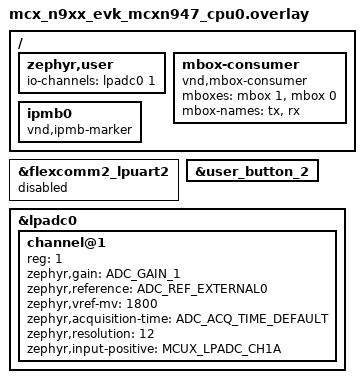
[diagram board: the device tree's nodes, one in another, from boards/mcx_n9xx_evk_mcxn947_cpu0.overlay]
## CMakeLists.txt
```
# SPDX-License-Identifier: Apache-2.0
#
# Full board port: builds real common/ subsystems (hal_wdt, hal_i2c,
# lib/timer, lib/libutil, sensor framework, FRU/eeprom, IPMI/IPMB)
# ported to mainline Zephyr's API surface, in place of the bring-up
# branch's from-scratch stand-ins. See README.md for exactly what was
# ported, what's stubbed, and why.

cmake_minimum_required(VERSION 3.20.0)

# DMTF libspdm (SPDM attestation responder, see src/plat_spdm.c) is
# pulled in as an extra Zephyr module so its zephyr_library() registers
# before find_package(Zephyr) finalises ZEPHYR_LIBS. Must precede it.
list(APPEND ZEPHYR_EXTRA_MODULES ${CMAKE_CURRENT_SOURCE_DIR}/libspdm)

find_package(Zephyr REQUIRED HINTS $ENV{ZEPHYR_BASE})
project(mcx-n9xx-evk)

set(common_path ${CMAKE_CURRENT_SOURCE_DIR}/../../common)

target_sources(app PRIVATE
  src/main.c
  src/plat_gpio.c
  src/plat_hwinfo.c
  src/plat_mbox.c
  src/plat_shell.c
  src/plat_storage.c
  src/plat_sensor_table.c
  src/plat_sdr_table.c
  src/plat_fru.c
  src/plat_ipmb.c
  src/plat_mctp.c
  src/plat_pldm_monitor.c
  src/plat_spdm.c
  src/plat_spdm_platform.c
  src/plat_stubs.c
  ${common_path}/lib/timer.c
  ${common_path}/lib/libutil.c
  ${common_path}/lib/util_pmbus.c
  ${common_path}/hal/hal_wdt.c
  ${common_path}/hal/hal_i2c.c
  ${common_path}/service/sensor/sensor.c
  ${common_path}/service/sensor/sdr.c
  ${common_path}/service/mctp/mctp.c
  ${common_path}/service/mctp/mctp_ctrl.c
  ${common_path}/service/mctp/mctp_smbus.c
  ${common_path}/service/pldm/pldm.c
  ${common_path}/service/pldm/pldm_base.c
  ${common_path}/service/pldm/pldm_oem.c
  ${common_path}/service/pldm/pldm_smbios.c
  ${common_path}/service/pldm/pldm_firmware_update.c
  ${common_path}/service/ipmb/ipmb.c
  ${common_path}/service/ipmi/ipmi.c
  ${common_path}/service/ipmi/app_handler.c
  ${common_path}/service/ipmi/chassis_handler.c
  ${common_path}/service/ipmi/sensor_handler.c
  ${common_path}/service/ipmi/storage_handler.c
  ${common_path}/service/ipmi/oem_handler.c
  ${common_path}/shell/commands/sensor_shell.c
)

# common/service/ipmi/oem_1s_handler.c implements Meta's proprietary
# OEM-1S NetFn (0x38) command set (fan/GPIO/JTAG/PECI/APML etc, all
# x86-host-adjacent BMC/BIC functionality). It unconditionally
# includes hal_gpio.h and hal_peci.h, neither portable to this board
# (see above/README.md), and none of its commands apply to an EVK with
# no host, fans, or PECI. ipmi.c's dispatch table calls
# IPMI_OEM_1S_handler() unconditionally for that NetFn regardless -
# stubbed (CC_INVALID_CMD, the honest "not implemented" answer) in
# src/plat_stubs.c.

# common/service/sensor/sensor.c's driver-dispatch table
# (sensor_drive_tbl) unconditionally references every possible sensor
# chip driver's init/read functions by type, regardless of what any
# given board's (empty, here) sensor table actually configures - every
# OpenBIC board compiles the whole common/dev/*.c glob for this reason.
# Excluded:
# - snoop.c/pcc.c: genuinely Aspeed-only hardware (SNOOP/POST Code
#   Capture peripherals) with no mainline equivalent, and (unlike
#   everything else here) not referenced by sensor_drive_tbl at all -
#   nothing needs them to link.
# - cx7.c/nv_satmc.c/mpro.c/pm8702.c/vistara.c: all need
#   pldm_monitor.c's pldm_platform_monitor_read(), which needs
#   hal_gpio.c - a hand-rolled, Aspeed/NPCM4XX-register-address-
#   specific GPIO driver, not a portable wrapper. Porting it is new
#   low-level driver work for MCXN947's own GPIO registers, out of
#   scope here (see README.md). cx7_init - the only one of these five
#   sensor_drive_tbl actually needs - is stubbed in plat_stubs.c.
file(GLOB dev_sources ${common_path}/dev/*.c)
list(REMOVE_ITEM dev_sources
  ${common_path}/dev/snoop.c
  ${common_path}/dev/pcc.c
  ${common_path}/dev/cx7.c
  ${common_path}/dev/nv_satmc.c
  ${common_path}/dev/mpro.c
  ${common_path}/dev/pm8702.c
  ${common_path}/dev/vistara.c
)
target_sources(app PRIVATE ${dev_sources})

target_include_directories(app PRIVATE
  src
  ${CMAKE_CURRENT_LIST_DIR}/include
  ${common_path}
  ${common_path}/hal
  ${common_path}/lib
  ${common_path}/dev/include
  ${common_path}/service/sensor
  ${common_path}/service/ipmb
  ${common_path}/service/pldm
  ${common_path}/service/mctp
  ${common_path}/service/ipmi/include
  ${common_path}/service/usb
  ${common_path}/shell/commands
)
```

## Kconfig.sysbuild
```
# SPDX-License-Identifier: Apache-2.0
#
# Selects the cpu1 ("remote") board target for the optional dual-core
# build (`west build --sysbuild`). Not needed for the normal cpu0-only
# build used by every other subsystem in this directory.

source "share/sysbuild/Kconfig"

config REMOTE_BOARD
	string "Remote (cpu1) board"
	default "mcx_n9xx_evk/mcxn947/cpu1" if $(BOARD) = "mcx_n9xx_evk"
```

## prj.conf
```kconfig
# Full board port: console + shell + real common/ subsystems (wdt,
# I2C, sensor framework, FRU/eeprom) ported to mainline Zephyr.
CONFIG_GPIO=y
CONFIG_LOG=y
CONFIG_LOG_BACKEND_UART=y
CONFIG_SHELL=y
CONFIG_SHELL_BACKEND_SERIAL_INIT_PRIORITY=99
CONFIG_REBOOT=y
CONFIG_HWINFO=y
CONFIG_HWINFO_SHELL=y
CONFIG_WATCHDOG=y
CONFIG_FLASH=y
CONFIG_FLASH_MAP=y
CONFIG_NVS=y
CONFIG_MBOX=y
CONFIG_I2C=y
CONFIG_I2C_SHELL=y
CONFIG_I2C_TARGET=y
CONFIG_ADC=y
# SPDM attestation responder (libspdm + its bundled mbedTLS - see
# libspdm/zephyr/CMakeLists.txt / src/plat_spdm.c). libspdm mallocs its
# context + scratch buffer from the libc heap; mbedTLS ECP/X.509 also
# allocate.
CONFIG_COMMON_LIBC_MALLOC=y
CONFIG_COMMON_LIBC_MALLOC_ARENA_SIZE=65536
CONFIG_ENTROPY_GENERATOR=y
# cmsis-os2 (used by common/lib/timer.c and common/hal/hal_wdt.c's
# wdt_thread) - CMSIS_RTOS_V2 itself depends on these
CONFIG_POLL=y
CONFIG_NUM_PREEMPT_PRIORITIES=56
CONFIG_CMSIS_RTOS_V2=y
CONFIG_HEAP_MEM_POOL_SIZE=16384
CONFIG_MAIN_STACK_SIZE=8192
```

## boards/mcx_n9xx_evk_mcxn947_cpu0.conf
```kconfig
# Board-specific config for the cpu0 app, applied to EVERY build of this
# target (single-core and sysbuild alike).
#
# NOTE: CONFIG_SECOND_CORE_MCUX is deliberately NOT set here. It makes
# cpu0's SoC init release cpu1 from reset pointing at slot1_partition;
# with no cpu1 image there (the normal single-core build) cpu1
# wild-branches through blank flash and wedges the system before the
# console is up. It is now set from sysbuild.cmake, scoped to the
# dual-core `west build --sysbuild` build where a cpu1 image actually
# exists.
```

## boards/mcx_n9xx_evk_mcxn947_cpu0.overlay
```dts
/* flexcomm2_lpi2c2 (LCD-shield header I2C) shares its physical FlexComm2
 * instance with flexcomm2_lpuart2, both of which the board's inherited
 * common dtsi (mcx_nx4x_evk_cpu0.dtsi, written for NXP's reference board
 * with an actual audio-codec header populated) enables simultaneously.
 * A single LP_FLEXCOMM instance can only run one peripheral function at
 * a time, and having both nodes "okay" left flexcomm2_lpi2c2's
 * clock_control_get_rate() returning 0 - confirmed on real hardware via
 * a temporary printk in LPI2C_GetCyclesForWidth (modules/hal/nxp/.../
 * fsl_lpi2c.c) showing sourceClock_Hz=0, which then hit a genuine
 * division by zero at fsl_lpi2c.c:166 during LPI2C_MasterInit (USAGE
 * FAULT, "Division by zero", every boot). Disabling the unused UART
 * node resolves the contention: flexcomm2_lpi2c2 now inits with a real
 * 48MHz source clock and the board boots clean - see README.md.
 */
&flexcomm2_lpuart2 {
	status = "disabled";
};

/* red_led (D2 red channel) is enabled by the board's own devicetree.
 *
 * user_button_2 (SW2, gpio1.3, active-low w/ pull-up) is disabled by
 * default on this board - enabled here for the GPIO status-monitoring
 * subsystem in src/plat_gpio.c, standing in for a real BIC's
 * power-good/host-presence input until actual platform signals are
 * wired up.
 */
&user_button_2 {
	status = "okay";
};

/* PLDM for Platform Monitoring and Control (DSP0248, type 0x02 - see
 * src/plat_pldm_monitor.c) needs at least one real sensor to be a
 * meaningful responder. The MCXN947 has an on-die temperature sensor
 * on LPADC channel 26A, but Zephyr's generic adc_read path doesn't
 * drive the temp-sensor CMDL loop/scale setup that SoC needs, so the
 * nxp,lpadc-temp40 reading came out unreliable and mis-scaled (see
 * README.md). Instead the board's numeric sensor is a plain
 * single-ended LPADC voltage read on ADC0_A1 (PIO4_15), one of the
 * three analog pins this EVK's pinmux_lpadc0 routes to the J2 header,
 * reported in millivolts. lpadc0 / vref are already status="okay" in
 * the board's own dtsi.
 */
#include <zephyr/dt-bindings/adc/adc.h>
#include <zephyr/dt-bindings/adc/mcux-lpadc.h>

&lpadc0 {
	#address-cells = <1>;
	#size-cells = <0>;

	channel@1 {
		reg = <1>;
		zephyr,gain = "ADC_GAIN_1";
		/* MCUX LPADC driver only accepts ADC_REF_EXTERNAL0/1;
		 * EXTERNAL0 = use the ADC's already-configured reference. */
		zephyr,reference = "ADC_REF_EXTERNAL0";
		zephyr,vref-mv = <1800>;
		zephyr,acquisition-time = <ADC_ACQ_TIME_DEFAULT>;
		zephyr,resolution = <12>;
		zephyr,input-positive = <MCUX_LPADC_CH1A>;
	};
};

/ {
	zephyr,user {
		io-channels = <&lpadc0 1>;
	};
};

/* Inter-core mailbox endpoint for the dual-core subsystem
 * (src/plat_mbox.c) - only exercised when built with sysbuild
 * (west build --sysbuild), pairing with remote/boards/
 * mcx_n9xx_evk_mcxn947_cpu1.overlay's swapped tx/rx channels.
 */
/ {
	mbox-consumer {
		compatible = "vnd,mbox-consumer";
		mboxes = <&mbox 1>, <&mbox 0>;
		mbox-names = "tx", "rx";
	};

	/* Marker node only - common/service/ipmb/ipmb.h gates DEV_IPMB_0
	 * on DT_NODE_EXISTS(DT_NODELABEL(ipmb0)) to decide whether an IPMB
	 * channel 0 is configured for this board at all. The actual
	 * transport (which physical I2C bus/address) is real
	 * i2c_target_register()-based code in hal_i2c.c, driven by
	 * src/plat_ipmb.c's IPMB_0_BUS/IPMB_0_SELF_ADDR - this node isn't
	 * bound to a Zephyr driver and carries no hardware meaning itself.
	 */
	ipmb0: ipmb0 {
		compatible = "vnd,ipmb-marker";
	};
};
```

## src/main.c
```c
/*
 * Copyright (c) Meta Platforms, Inc. and affiliates.
 *
 * Licensed under the Apache License, Version 2.0 (the "License");
 * you may not use this file except in compliance with the License.
 * You may obtain a copy of the License at
 *
 *     http://www.apache.org/licenses/LICENSE-2.0
 *
 * Unless required by applicable law or agreed to in writing, software
 * distributed under the License is distributed on an "AS IS" BASIS,
 * WITHOUT WARRANTIES OR CONDITIONS OF ANY KIND, either express or implied.
 * See the License for the specific language governing permissions and
 * limitations under the License.
 *
 * Full-board-port main() for the MCX-N9XX-EVK: calls the *real*
 * common/ init pipeline (wdt_init, util_init_timer, util_init_I2C,
 * sensor_init, FRU_init, ipmi_init) ported to mainline Zephyr, instead
 * of the bring-up branch's from-scratch stand-ins. ipmi_init() brings
 * up a real IPMB-over-I2C channel in target/slave mode on
 * flexcomm2_lpi2c2 (see README.md's "IPMI transport" section) -
 * replacing the earlier standalone plat_i2c_target.c proof-of-concept
 * on that same bus/address, now superseded. util_init_i3c() still
 * isn't called (see README.md - hal_i3c.c needs Aspeed-only APIs). A
 * separate real-I3C attempt (plat_i3c.c, i3c_do_daa() against
 * mainline's own I3C API) was tried and reverted: enabling
 * CONFIG_I3C=y alone made the board hang before main() ever runs (no
 * boot banner at all) - a mainline I3C_MCUX driver-level issue for
 * this SoC, not something introduced by that new code. See README.md
 * for the full writeup.
 */

#include <zephyr/kernel.h>
#include <zephyr/drivers/gpio.h>

#include "fru.h"
#include "hal_i2c.h"
#include "hal_wdt.h"
#include "ipmi.h"
#include "libutil.h"
#include "plat_gpio.h"
#include "plat_hwinfo.h"
#include "plat_mbox.h"
#include "plat_mctp.h"
#include "plat_pldm_monitor.h"
#include "plat_spdm.h"
#include "plat_storage.h"
#include "plat_version.h"
#include "sensor.h"
#include "timer.h"

#define HEARTBEAT_PERIOD_MS 500
#define MBOX_PING_PERIOD_MS 2000

static const struct gpio_dt_spec heartbeat_led = GPIO_DT_SPEC_GET(DT_ALIAS(led0), gpios);

int main(void)
{
	printk("\n"
	       "  ___                   ____ ___ ____\n"
	       " / _ \\ _ __   ___ _ __ | __ )_ _/ ___|\n"
	       "| | | | '_ \\ / _ \\ '_ \\|  _ \\| | |\n"
	       "| |_| | |_) |  __/ | | | |_) | | |___\n"
	       " \\___/| .__/ \\___|_| |_|____/___\\____|\n"
	       "      |_|\n");
	printk("Hello, welcome to OpenBIC / %s %s %x%x.%x.%x\n", PLATFORM_NAME, PROJECT_NAME,
	       BIC_FW_YEAR_MSB, BIC_FW_YEAR_LSB, BIC_FW_WEEK, BIC_FW_VER);
	printk("Full board port: real common/ wdt/timer/I2C/sensor/FRU/IPMI init.\n");

	plat_hwinfo_init();
	plat_storage_init();
	plat_gpio_init();
	plat_mbox_init();

	wdt_init();
	util_init_timer();
	util_init_I2C();
	sensor_init();
	FRU_init();
	ipmi_init();
	plat_mctp_init();
	plat_pldm_monitor_init();
	plat_spdm_init();

	if (!gpio_is_ready_dt(&heartbeat_led)) {
		printk("Heartbeat LED device not ready\n");
		return 0;
	}

	gpio_pin_configure_dt(&heartbeat_led, GPIO_OUTPUT_ACTIVE);

	int loop_count = 0;

	while (1) {
		gpio_pin_toggle_dt(&heartbeat_led);
		if (++loop_count % (MBOX_PING_PERIOD_MS / HEARTBEAT_PERIOD_MS) == 0) {
			plat_mbox_ping();
		}
		k_msleep(HEARTBEAT_PERIOD_MS);
	}

	return 0;
}
```

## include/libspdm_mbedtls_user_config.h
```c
/* SPDX-License-Identifier: Apache-2.0 */
/*
 * mbedTLS user config for the libspdm build, layered on top of libspdm's
 * bundled include/mbedtls/libspdm_mbedtls_config.h (included last by
 * mbedtls/build_info.h).
 *
 * Zephyr + picolibc: mbedtls's bundled platform_util.c recognises no
 * POSIX clock path and falls through to
 *   #error "No mbedtls_ms_time available"
 * The MCXN947 EVK also has no wired RTC. Route both time hooks to a
 * fixed epoch plus kernel uptime (src/plat_mbedtls_platform.c) - enough
 * for deterministic x509 validity math on the device cert chain.
 */
#ifndef LIBSPDM_MBEDTLS_USER_CONFIG_H
#define LIBSPDM_MBEDTLS_USER_CONFIG_H

#include <time.h>

time_t plat_mbedtls_time(time_t *timer);

#define MBEDTLS_PLATFORM_MS_TIME_ALT
#define MBEDTLS_PLATFORM_TIME_MACRO  plat_mbedtls_time

#endif /* LIBSPDM_MBEDTLS_USER_CONFIG_H */
```

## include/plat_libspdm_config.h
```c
/*
 * Copyright (c) Meta Platforms, Inc. and affiliates.
 *
 * Licensed under the Apache License, Version 2.0 (the "License");
 * you may not use this file except in compliance with the License.
 * You may obtain a copy of the License at
 *
 *     http://www.apache.org/licenses/LICENSE-2.0
 *
 * Unless required by applicable law or agreed to in writing, software
 * distributed under the License is distributed on an "AS IS" BASIS,
 * WITHOUT WARRANTIES OR CONDITIONS OF ANY KIND, either express or implied.
 * See the License for the specific language governing permissions and
 * limitations under the License.
 *
 * libspdm build configuration for the MCX-N9XX-EVK SPDM responder
 * (pointed at by -DLIBSPDM_CONFIG). Every knob in libspdm's
 * include/library/spdm_lib_config.h is #ifndef-guarded, so this file
 * only states the deltas from upstream and then #includes the upstream
 * file to fill in every default we don't care about (robust across
 * libspdm version bumps).
 *
 * Shape: attestation-only responder - identity (certificate),
 * CHALLENGE, and MEASUREMENTS. No secure sessions, key exchange, PSK,
 * mutual auth, chunking, CSR, or events. mbedTLS crypto backend, ECDSA
 * P-256/P-384 + SHA-256/SHA-384 only.
 */

#ifndef PLAT_LIBSPDM_CONFIG_H
#define PLAT_LIBSPDM_CONFIG_H

/* ---- responder capabilities: keep CERT + CHAL + MEAS, drop the rest */
#define LIBSPDM_ENABLE_CAPABILITY_CERT_CAP 1
#define LIBSPDM_ENABLE_CAPABILITY_CHAL_CAP 1
#define LIBSPDM_ENABLE_CAPABILITY_MEAS_CAP 1

#define LIBSPDM_ENABLE_CAPABILITY_KEY_EX_CAP 0
#define LIBSPDM_ENABLE_CAPABILITY_PSK_CAP 0
#define LIBSPDM_ENABLE_CAPABILITY_HBEAT_CAP 0
#define LIBSPDM_ENABLE_CAPABILITY_MUT_AUTH_CAP 0
#define LIBSPDM_ENABLE_CAPABILITY_ENCAP_CAP 0
#define LIBSPDM_ENABLE_CAPABILITY_CSR_CAP 0
#define LIBSPDM_ENABLE_CAPABILITY_CSR_CAP_EX 0
#define LIBSPDM_ENABLE_CAPABILITY_SET_CERT_CAP 0
#define LIBSPDM_ENABLE_CAPABILITY_CHUNK_CAP 0
#define LIBSPDM_ENABLE_CAPABILITY_MEL_CAP 0
#define LIBSPDM_ENABLE_CAPABILITY_EVENT_CAP 0
#define LIBSPDM_ENABLE_CAPABILITY_GET_KEY_PAIR_INFO_CAP 0
#define LIBSPDM_ENABLE_CAPABILITY_SET_KEY_PAIR_INFO_CAP 0
#define LIBSPDM_ENABLE_CAPABILITY_ENDPOINT_INFO_CAP 0
#define LIBSPDM_ENABLE_VENDOR_DEFINED_MESSAGES 0

/* requester-side sends: responder-only build */
#define LIBSPDM_SEND_GET_CERTIFICATE_SUPPORT 0
#define LIBSPDM_SEND_CHALLENGE_SUPPORT 0
#define LIBSPDM_SEND_GET_ENDPOINT_INFO_SUPPORT 0
#define LIBSPDM_EVENT_RECIPIENT_SUPPORT 0
#define LIBSPDM_RESPOND_IF_READY_SUPPORT 1

/* ---- crypto algorithm support ------------------------------------- */
#define LIBSPDM_RSA_SSA_SUPPORT 0
#define LIBSPDM_RSA_PSS_SUPPORT 0
#define LIBSPDM_ECDSA_SUPPORT 1
#define LIBSPDM_SM2_DSA_SUPPORT 0
#define LIBSPDM_EDDSA_ED25519_SUPPORT 0
#define LIBSPDM_EDDSA_ED448_SUPPORT 0

#define LIBSPDM_FFDHE_SUPPORT 0
#define LIBSPDM_ECDHE_SUPPORT 0
#define LIBSPDM_SM2_KEY_EXCHANGE_SUPPORT 0

#define LIBSPDM_AEAD_GCM_SUPPORT 0
#define LIBSPDM_AEAD_CHACHA20_POLY1305_SUPPORT 0
#define LIBSPDM_AEAD_SM4_SUPPORT 0

#define LIBSPDM_SHA256_SUPPORT 1
#define LIBSPDM_SHA384_SUPPORT 1
#define LIBSPDM_SHA512_SUPPORT 0
#define LIBSPDM_SHA3_256_SUPPORT 0
#define LIBSPDM_SHA3_384_SUPPORT 0
#define LIBSPDM_SHA3_512_SUPPORT 0
#define LIBSPDM_SM3_256_SUPPORT 0

/* ---- sizing (this is a 320 KB SRAM part) ------------------------- */
#define LIBSPDM_MAX_SPDM_MSG_SIZE 0x1200
#define LIBSPDM_MAX_CERT_CHAIN_SIZE 0x1000
#define LIBSPDM_MAX_MEASUREMENT_RECORD_SIZE 0x400

/* no secure sessions; context still sizes a few arrays off this */
#define LIBSPDM_MAX_SESSION_COUNT 1

/* ---- misc ------------------------------------------------------- */
#define LIBSPDM_DEBUG_ENABLE 0
#define LIBSPDM_FIPS_MODE 0

/* pull in every default we did not override above */
#include "library/spdm_lib_config.h"

#endif /* PLAT_LIBSPDM_CONFIG_H */
```

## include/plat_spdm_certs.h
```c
/* Auto-generated: EC P-256 dev identity for the SPDM responder.
 * Self-signed, single-cert chain (root == leaf). Dev / bring-up key
 * material - NOT production; this EVK has no secure key store. The
 * private key sits in flash. Regenerate per the README.
 */
#ifndef PLAT_SPDM_CERTS_H
#define PLAT_SPDM_CERTS_H
#include <stdint.h>

static const uint8_t plat_spdm_dev_cert_der[] = {
	0x30, 0x82, 0x01, 0xd6, 0x30, 0x82, 0x01, 0x7b, 0xa0, 0x03, 0x02, 0x01,
	0x02, 0x02, 0x14, 0x6c, 0x5d, 0x19, 0xcf, 0x8b, 0xd8, 0xc3, 0x46, 0x3b,
	0xe7, 0x63, 0x03, 0x41, 0x91, 0x87, 0x48, 0x7d, 0xe2, 0x4f, 0x37, 0x30,
	0x0a, 0x06, 0x08, 0x2a, 0x86, 0x48, 0xce, 0x3d, 0x04, 0x03, 0x02, 0x30,
	0x40, 0x31, 0x0c, 0x30, 0x0a, 0x06, 0x03, 0x55, 0x04, 0x0a, 0x0c, 0x03,
	0x4e, 0x58, 0x50, 0x31, 0x30, 0x30, 0x2e, 0x06, 0x03, 0x55, 0x04, 0x03,
	0x0c, 0x27, 0x4d, 0x43, 0x58, 0x2d, 0x4e, 0x39, 0x58, 0x58, 0x2d, 0x45,
	0x56, 0x4b, 0x20, 0x4f, 0x70, 0x65, 0x6e, 0x42, 0x49, 0x43, 0x20, 0x53,
	0x50, 0x44, 0x4d, 0x20, 0x64, 0x65, 0x76, 0x20, 0x72, 0x65, 0x73, 0x70,
	0x6f, 0x6e, 0x64, 0x65, 0x72, 0x30, 0x1e, 0x17, 0x0d, 0x32, 0x36, 0x30,
	0x38, 0x32, 0x38, 0x31, 0x32, 0x32, 0x35, 0x30, 0x36, 0x5a, 0x17, 0x0d,
	0x33, 0x36, 0x30, 0x38, 0x32, 0x35, 0x31, 0x32, 0x32, 0x35, 0x30, 0x36,
	0x5a, 0x30, 0x40, 0x31, 0x0c, 0x30, 0x0a, 0x06, 0x03, 0x55, 0x04, 0x0a,
	0x0c, 0x03, 0x4e, 0x58, 0x50, 0x31, 0x30, 0x30, 0x2e, 0x06, 0x03, 0x55,
	0x04, 0x03, 0x0c, 0x27, 0x4d, 0x43, 0x58, 0x2d, 0x4e, 0x39, 0x58, 0x58,
	0x2d, 0x45, 0x56, 0x4b, 0x20, 0x4f, 0x70, 0x65, 0x6e, 0x42, 0x49, 0x43,
	0x20, 0x53, 0x50, 0x44, 0x4d, 0x20, 0x64, 0x65, 0x76, 0x20, 0x72, 0x65,
	0x73, 0x70, 0x6f, 0x6e, 0x64, 0x65, 0x72, 0x30, 0x59, 0x30, 0x13, 0x06,
	0x07, 0x2a, 0x86, 0x48, 0xce, 0x3d, 0x02, 0x01, 0x06, 0x08, 0x2a, 0x86,
	0x48, 0xce, 0x3d, 0x03, 0x01, 0x07, 0x03, 0x42, 0x00, 0x04, 0x0f, 0x89,
	0x89, 0xf3, 0x25, 0x13, 0xcc, 0xa9, 0x3a, 0xe6, 0xe1, 0x59, 0x63, 0x29,
	0xb5, 0xa5, 0xc3, 0x71, 0xab, 0x97, 0xf1, 0x9f, 0xc8, 0x78, 0x42, 0xdd,
	0x78, 0xaf, 0xc3, 0xb7, 0xfa, 0x7e, 0x2c, 0xf3, 0x9d, 0x60, 0x89, 0xa2,
	0xea, 0x4b, 0x2d, 0xfe, 0x51, 0x2d, 0x2a, 0xd4, 0xc0, 0x58, 0xdc, 0x70,
	0x0f, 0xb7, 0xc8, 0x3c, 0xa0, 0x1c, 0x0c, 0xed, 0x63, 0x2f, 0x5e, 0xa4,
	0xcd, 0xd7, 0xa3, 0x53, 0x30, 0x51, 0x30, 0x1d, 0x06, 0x03, 0x55, 0x1d,
	0x0e, 0x04, 0x16, 0x04, 0x14, 0xcc, 0xee, 0x3e, 0x10, 0xcc, 0x0d, 0x97,
	0xff, 0xdf, 0x08, 0x6a, 0xf2, 0x1a, 0x52, 0xab, 0x7f, 0xe8, 0x4e, 0x37,
	0x72, 0x30, 0x1f, 0x06, 0x03, 0x55, 0x1d, 0x23, 0x04, 0x18, 0x30, 0x16,
	0x80, 0x14, 0xcc, 0xee, 0x3e, 0x10, 0xcc, 0x0d, 0x97, 0xff, 0xdf, 0x08,
	0x6a, 0xf2, 0x1a, 0x52, 0xab, 0x7f, 0xe8, 0x4e, 0x37, 0x72, 0x30, 0x0f,
	0x06, 0x03, 0x55, 0x1d, 0x13, 0x01, 0x01, 0xff, 0x04, 0x05, 0x30, 0x03,
	0x01, 0x01, 0xff, 0x30, 0x0a, 0x06, 0x08, 0x2a, 0x86, 0x48, 0xce, 0x3d,
	0x04, 0x03, 0x02, 0x03, 0x49, 0x00, 0x30, 0x46, 0x02, 0x21, 0x00, 0x83,
	0xca, 0x7d, 0x69, 0x9b, 0x0e, 0xca, 0x74, 0x2f, 0x0c, 0x31, 0xf1, 0x95,
	0x28, 0x99, 0x68, 0x17, 0x0e, 0x90, 0x52, 0x49, 0x69, 0xf8, 0x11, 0xa2,
	0xfd, 0x42, 0xbf, 0xaf, 0x5c, 0x6a, 0x32, 0x02, 0x21, 0x00, 0x9d, 0x7f,
	0x37, 0x7f, 0xe0, 0x89, 0x2b, 0x2d, 0xfc, 0xcf, 0x3d, 0x5e, 0x83, 0xb3,
	0x22, 0x7f, 0x22, 0xda, 0x0d, 0xbc, 0x0d, 0x77, 0x6b, 0xee, 0xb2, 0x4d,
	0x79, 0xd7, 0x50, 0x8d, 0xf8, 0x7d,
};
static const uint32_t plat_spdm_dev_cert_der_len = 474;

static const uint8_t plat_spdm_dev_priv[] = {
	0x50, 0x35, 0xb3, 0xe9, 0xc2, 0x6a, 0x70, 0xe2, 0xe5, 0xc5, 0x90, 0x95,
	0x93, 0x25, 0x22, 0x1d, 0x1d, 0x6f, 0x70, 0x6a, 0x49, 0x42, 0x85, 0xba,
	0x51, 0x19, 0x4a, 0xbf, 0x33, 0x1e, 0x6a, 0xe3,
};
static const uint32_t plat_spdm_dev_priv_len = 32;

/* Uncompressed EC point X||Y (0x04 prefix stripped) - the same public
 * key carried in the cert above. Used to populate the signing context
 * (mbedTLS can sign from d alone, but libspdm's sample path sets both). */
static const uint8_t plat_spdm_dev_pub[] = {
	0x0f, 0x89, 0x89, 0xf3, 0x25, 0x13, 0xcc, 0xa9, 0x3a, 0xe6, 0xe1, 0x59,
	0x63, 0x29, 0xb5, 0xa5, 0xc3, 0x71, 0xab, 0x97, 0xf1, 0x9f, 0xc8, 0x78,
	0x42, 0xdd, 0x78, 0xaf, 0xc3, 0xb7, 0xfa, 0x7e, 0x2c, 0xf3, 0x9d, 0x60,
	0x89, 0xa2, 0xea, 0x4b, 0x2d, 0xfe, 0x51, 0x2d, 0x2a, 0xd4, 0xc0, 0x58,
	0xdc, 0x70, 0x0f, 0xb7, 0xc8, 0x3c, 0xa0, 0x1c, 0x0c, 0xed, 0x63, 0x2f,
	0x5e, 0xa4, 0xcd, 0xd7,
};
static const uint32_t plat_spdm_dev_pub_len = 64;

#endif /* PLAT_SPDM_CERTS_H */
```

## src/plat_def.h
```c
/*
 * Copyright (c) Meta Platforms, Inc. and affiliates.
 *
 * Licensed under the Apache License, Version 2.0 (the "License");
 * you may not use this file except in compliance with the License.
 * You may obtain a copy of the License at
 *
 *     http://www.apache.org/licenses/LICENSE-2.0
 *
 * Unless required by applicable law or agreed to in writing, software
 * distributed under the License is distributed on an "AS IS" BASIS,
 * WITHOUT WARRANTIES OR CONDITIONS OF ANY KIND, either express or implied.
 * See the License for the specific language governing permissions and
 * limitations under the License.
 *
 * Board-wide constants required by common/. This board has no
 * defined sensors/FRU/host bridge yet, so this is intentionally
 * minimal.
 */

#ifndef PLAT_DEF_H
#define PLAT_DEF_H

#endif
```

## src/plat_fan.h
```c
/*
 * Copyright (c) Meta Platforms, Inc. and affiliates.
 *
 * Licensed under the Apache License, Version 2.0 (the "License");
 * you may not use this file except in compliance with the License.
 * You may obtain a copy of the License at
 *
 *     http://www.apache.org/licenses/LICENSE-2.0
 *
 * Unless required by applicable law or agreed to in writing, software
 * distributed under the License is distributed on an "AS IS" BASIS,
 * WITHOUT WARRANTIES OR CONDITIONS OF ANY KIND, either express or implied.
 * See the License for the specific language governing permissions and
 * limitations under the License.
 *
 * Required by common/service/ipmi/oem_handler.c's include chain. This
 * board has no fans - pal_set_fan_duty() (src/plat_stubs.c) always
 * fails, honestly reporting "not supported" rather than pretending to
 * control real hardware.
 */

#ifndef PLAT_FAN_H
#define PLAT_FAN_H

#include <stdint.h>

#define MAX_FAN_DUTY_VALUE 100
#define MAX_FAN_PWM_INDEX_COUNT 0
#define INDEX_ALL_PWM 0xFF

enum { FAN_AUTO_MODE = 0, FAN_MANUAL_MODE = 1 };

int pal_set_fan_duty(uint8_t pwm_id, uint8_t duty, uint8_t slot_index);
int pal_get_fan_ctrl_mode(uint8_t *mode);
void pal_set_fan_ctrl_mode(uint8_t mode);

#endif
```

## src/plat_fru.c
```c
/*
 * Copyright (c) Meta Platforms, Inc. and affiliates.
 *
 * Licensed under the Apache License, Version 2.0 (the "License");
 * you may not use this file except in compliance with the License.
 * You may obtain a copy of the License at
 *
 *     http://www.apache.org/licenses/LICENSE-2.0
 *
 * Unless required by applicable law or agreed to in writing, software
 * distributed under the License is distributed on an "AS IS" BASIS,
 * WITHOUT WARRANTIES OR CONDITIONS OF ANY KIND, either express or implied.
 * See the License for the specific language governing permissions and
 * limitations under the License.
 *
 * No physical FRU EEPROM is present on this EVK. This config points
 * real FRU_read()/FRU_write() at a plausible 24C-series EEPROM address
 * (0x50) on the Arduino-header I2C bus - a real I2C transaction that
 * will genuinely NACK/timeout, which is the honest, correct behavior
 * given the hardware (see common/dev/fru.c's graceful error handling
 * and meta-facebook/mcx-n9xx-evk/README.md).
 */

#include <string.h>
#include "fru.h"
#include "plat_fru.h"
#include "plat_i2c.h"

#define MCX_N9XX_EVK_FRU_PORT I2C_BUS_ARDUINO_HEADER
#define MCX_N9XX_EVK_FRU_ADDR (0xA0 >> 1)

const EEPROM_CFG plat_fru_config[] = {
	{
		NV_ATMEL_24C128,
		MCX_N9XX_EVK_FRU_ID,
		MCX_N9XX_EVK_FRU_PORT,
		MCX_N9XX_EVK_FRU_ADDR,
		FRU_DEV_ACCESS_BYTE,
		FRU_START,
		FRU_SIZE,
	},
};

void pal_load_fru_config(void)
{
	memcpy(&fru_config, &plat_fru_config, sizeof(plat_fru_config));
}
```

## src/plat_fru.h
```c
/*
 * Copyright (c) Meta Platforms, Inc. and affiliates.
 *
 * Licensed under the Apache License, Version 2.0 (the "License");
 * you may not use this file except in compliance with the License.
 * You may obtain a copy of the License at
 *
 *     http://www.apache.org/licenses/LICENSE-2.0
 *
 * Unless required by applicable law or agreed to in writing, software
 * distributed under the License is distributed on an "AS IS" BASIS,
 * WITHOUT WARRANTIES OR CONDITIONS OF ANY KIND, either express or implied.
 * See the License for the specific language governing permissions and
 * limitations under the License.
 */

#ifndef PLAT_FRU_H
#define PLAT_FRU_H

enum FRU_ID {
	MCX_N9XX_EVK_FRU_ID,
	MAX_FRU_ID,
};

#define FRU_CFG_NUM MAX_FRU_ID

#endif
```

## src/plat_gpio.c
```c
/*
 * Copyright (c) Meta Platforms, Inc. and affiliates.
 *
 * Licensed under the Apache License, Version 2.0 (the "License");
 * you may not use this file except in compliance with the License.
 * You may obtain a copy of the License at
 *
 *     http://www.apache.org/licenses/LICENSE-2.0
 *
 * Unless required by applicable law or agreed to in writing, software
 * distributed under the License is distributed on an "AS IS" BASIS,
 * WITHOUT WARRANTIES OR CONDITIONS OF ANY KIND, either express or implied.
 * See the License for the specific language governing permissions and
 * limitations under the License.
 *
 * Real GPIO status-monitoring subsystem, ported to mainline Zephyr's
 * gpio API from scratch (not common/hal/hal_gpio.c - see the top-level
 * README for why that file isn't buildable against upstream Zephyr).
 *
 * This EVK has no on-board sensor to read, so SW2 (the "mon0" alias)
 * stands in for what would be a real platform status input on an
 * actual BIC target (power-good, host presence, etc.) - same GPIO
 * edge-interrupt + debounce pattern, real hardware, just a stand-in
 * signal source.
 */

#include <zephyr/kernel.h>
#include <zephyr/drivers/gpio.h>
#include <zephyr/logging/log.h>

#include "plat_gpio.h"

LOG_MODULE_REGISTER(plat_gpio, LOG_LEVEL_INF);

#define DEBOUNCE_MS 30

static const struct gpio_dt_spec mon0 = GPIO_DT_SPEC_GET(DT_ALIAS(sw0), gpios);
static struct gpio_callback mon0_cb_data;
static struct k_work_delayable mon0_debounce_work;
static atomic_t mon0_state;

/* Board hook, __weak so subsystems that care about SW2 transitions
 * (e.g. plat_pldm_monitor.c, which turns them into PLDM state-sensor
 * events) can observe them without this file depending on them.
 * Runs in the system workqueue, after debounce. */
__weak void plat_gpio_mon0_changed(int level)
{
	ARG_UNUSED(level);
}

static void mon0_debounce_handler(struct k_work *work)
{
	ARG_UNUSED(work);

	int level = gpio_pin_get_dt(&mon0);

	if (level < 0) {
		LOG_ERR("mon0 read failed: %d", level);
		return;
	}

	if (atomic_set(&mon0_state, level) != level) {
		LOG_INF("mon0 (SW2) state changed: %s", level ? "asserted" : "deasserted");
		plat_gpio_mon0_changed(level);
	}
}

static void mon0_isr(const struct device *port, struct gpio_callback *cb, gpio_port_pins_t pins)
{
	ARG_UNUSED(port);
	ARG_UNUSED(cb);
	ARG_UNUSED(pins);

	k_work_reschedule(&mon0_debounce_work, K_MSEC(DEBOUNCE_MS));
}

void plat_gpio_init(void)
{
	int ret;

	if (!gpio_is_ready_dt(&mon0)) {
		LOG_ERR("mon0 device not ready");
		return;
	}

	ret = gpio_pin_configure_dt(&mon0, GPIO_INPUT);
	if (ret < 0) {
		LOG_ERR("mon0 configure failed: %d", ret);
		return;
	}

	ret = gpio_pin_interrupt_configure_dt(&mon0, GPIO_INT_EDGE_BOTH);
	if (ret < 0) {
		LOG_ERR("mon0 interrupt configure failed: %d", ret);
		return;
	}

	k_work_init_delayable(&mon0_debounce_work, mon0_debounce_handler);
	gpio_init_callback(&mon0_cb_data, mon0_isr, BIT(mon0.pin));
	gpio_add_callback(mon0.port, &mon0_cb_data);

	atomic_set(&mon0_state, gpio_pin_get_dt(&mon0));
	LOG_INF("mon0 (SW2) monitoring started, initial state: %s",
		atomic_get(&mon0_state) ? "asserted" : "deasserted");
}

int plat_gpio_mon0_get(void)
{
	return atomic_get(&mon0_state);
}
```

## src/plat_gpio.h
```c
/*
 * Copyright (c) Meta Platforms, Inc. and affiliates.
 *
 * Licensed under the Apache License, Version 2.0 (the "License");
 * you may not use this file except in compliance with the License.
 * You may obtain a copy of the License at
 *
 *     http://www.apache.org/licenses/LICENSE-2.0
 *
 * Unless required by applicable law or agreed to in writing, software
 * distributed under the License is distributed on an "AS IS" BASIS,
 * WITHOUT WARRANTIES OR CONDITIONS OF ANY KIND, either express or implied.
 * See the License for the specific language governing permissions and
 * limitations under the License.
 */

#ifndef PLAT_GPIO_H
#define PLAT_GPIO_H

/* Sets up interrupt-driven monitoring of the mon0 GPIO (SW2 on this EVK,
 * standing in for a real platform status signal - see plat_gpio.c).
 * Logs every state transition; current state is also queryable live via
 * the "plat gpio mon0" shell command.
 */
void plat_gpio_init(void);

/* Current debounced level of the monitored GPIO: 1 = asserted, 0 = not. */
int plat_gpio_mon0_get(void);

/* Called once per debounced mon0 (SW2) transition, from the system
 * workqueue. __weak no-op by default; override to react. */
void plat_gpio_mon0_changed(int level);

#endif
```

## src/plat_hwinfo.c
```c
/*
 * Copyright (c) Meta Platforms, Inc. and affiliates.
 *
 * Licensed under the Apache License, Version 2.0 (the "License");
 * you may not use this file except in compliance with the License.
 * You may obtain a copy of the License at
 *
 *     http://www.apache.org/licenses/LICENSE-2.0
 *
 * Unless required by applicable law or agreed to in writing, software
 * distributed under the License is distributed on an "AS IS" BASIS,
 * WITHOUT WARRANTIES OR CONDITIONS OF ANY KIND, either express or implied.
 * See the License for the specific language governing permissions and
 * limitations under the License.
 */

#include <zephyr/kernel.h>
#include <zephyr/drivers/hwinfo.h>
#include <zephyr/logging/log.h>
#include <stdbool.h>
#include <string.h>

#include "plat_hwinfo.h"

LOG_MODULE_REGISTER(plat_hwinfo, LOG_LEVEL_INF);

static uint8_t device_id[16];
static size_t device_id_len;
static uint32_t reset_cause;

static const char *reset_cause_str(uint32_t cause)
{
	if (cause & RESET_PIN) {
		return "pin";
	}
	if (cause & RESET_SOFTWARE) {
		return "software";
	}
	if (cause & RESET_WATCHDOG) {
		return "watchdog";
	}
	if (cause & RESET_POR) {
		return "power-on";
	}
	if (cause == 0) {
		return "unknown/not-supported";
	}
	return "other";
}

void plat_hwinfo_init(void)
{
	ssize_t ret;
	char hex[sizeof(device_id) * 2 + 1] = {0};

	ret = hwinfo_get_device_id(device_id, sizeof(device_id));
	if (ret > 0) {
		device_id_len = (size_t)ret;
		for (size_t i = 0; i < device_id_len; i++) {
			snprintf(&hex[i * 2], 3, "%02x", device_id[i]);
		}
		LOG_INF("device id: %s", hex);
	} else {
		LOG_ERR("hwinfo_get_device_id failed: %d", (int)ret);
	}

	if (hwinfo_get_reset_cause(&reset_cause) == 0) {
		LOG_INF("last reset cause: %s (0x%08x)", reset_cause_str(reset_cause),
			reset_cause);
		hwinfo_clear_reset_cause();
	} else {
		LOG_ERR("hwinfo_get_reset_cause failed");
	}
}

bool plat_get_device_id(uint8_t *out, size_t out_len)
{
	if (!out || out_len < sizeof(device_id) || device_id_len == 0) {
		return false;
	}

	memcpy(out, device_id, device_id_len);
	if (device_id_len < sizeof(device_id)) {
		/* Shouldn't happen on this SoC (always returns a full 16
		 * bytes), but zero-pad rather than leave the tail
		 * uninitialized if hwinfo ever returns fewer. */
		memset(out + device_id_len, 0, sizeof(device_id) - device_id_len);
	}
	return true;
}
```

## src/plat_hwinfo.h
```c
/*
 * Copyright (c) Meta Platforms, Inc. and affiliates.
 *
 * Licensed under the Apache License, Version 2.0 (the "License");
 * you may not use this file except in compliance with the License.
 * You may obtain a copy of the License at
 *
 *     http://www.apache.org/licenses/LICENSE-2.0
 *
 * Unless required by applicable law or agreed to in writing, software
 * distributed under the License is distributed on an "AS IS" BASIS,
 * WITHOUT WARRANTIES OR CONDITIONS OF ANY KIND, either express or implied.
 * See the License for the specific language governing permissions and
 * limitations under the License.
 */

#ifndef PLAT_HWINFO_H
#define PLAT_HWINFO_H

#include <stdbool.h>
#include <stddef.h>
#include <stdint.h>

/* Reads and logs the chip's unique device ID and the cause of the last
 * reset - stand-ins for the device-identity data a real BIC reports
 * over IPMI (Get Device ID, Get Device GUID). Clears the reset-cause
 * latch after reading, per hwinfo API convention.
 */
void plat_hwinfo_init(void);

/* Copies the 16-byte device ID read by plat_hwinfo_init() into out
 * (out_len must be >= 16). Returns false if hwinfo_get_device_id()
 * never succeeded at boot. Used as this board's real, unique value for
 * MCTP Control's Get Endpoint UUID (see plat_mctp.c) - a genuine
 * per-chip silicon ID rather than a fabricated placeholder.
 */
bool plat_get_device_id(uint8_t *out, size_t out_len);

#endif
```

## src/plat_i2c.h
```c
/*
 * Copyright (c) Meta Platforms, Inc. and affiliates.
 *
 * Licensed under the Apache License, Version 2.0 (the "License");
 * you may not use this file except in compliance with the License.
 * You may obtain a copy of the License at
 *
 *     http://www.apache.org/licenses/LICENSE-2.0
 *
 * Unless required by applicable law or agreed to in writing, software
 * distributed under the License is distributed on an "AS IS" BASIS,
 * WITHOUT WARRANTIES OR CONDITIONS OF ANY KIND, either express or implied.
 * See the License for the specific language governing permissions and
 * limitations under the License.
 *
 * Board-specific I2C bus map for the MCX-N9XX-EVK. hal_i2c's bus
 * indices are firmware-internal (0-based). Both buses are physically
 * on the same Arduino-compatible header, J2 - see README.md for the
 * verified pin table.
 *
 * flexcomm2_lpi2c2 is the single sideband bus: it carries *both* the
 * IPMB-over-I2C channel (target mode, 7-bit addr 0x20 - see
 * plat_ipmb.h) *and* the MCTP-over-SMBus endpoint (target mode, 7-bit
 * addr 0x10 - see plat_mctp.c), as two independent slave-address
 * matches on the one LPI2C instance. This is the "one physical bus
 * carries IPMI + MCTP/PLDM (+ SPDM)" arrangement. It relies on the
 * LPI2C driver patch that programs address0/address1 and demuxes the
 * slave IRQ by matched address (drivers/i2c/i2c_mcux_lpi2c.c in the
 * wrouwet/zephyr fork) - mainline only matched one address per
 * instance. Used to crash at boot with a real divide-by-zero in NXP's
 * own MCUX LPI2C driver - see the overlay for that root cause (a
 * FlexComm2 clock conflict with the unused flexcomm2_lpuart2 node)
 * and README.md for the full writeup.
 *
 * flexcomm3_lpi2c3 is now controller-mode only (i2c scan/read/write);
 * it no longer hosts an MCTP target. Kept enabled as a spare
 * controller bus on J2 pins 15/17.
 */

#ifndef PLAT_I2C_H
#define PLAT_I2C_H

#include "hal_i2c.h"

#define I2C_BUS_MAX_NUM 4

#define I2C_BUS_ARDUINO_HEADER 3 /* flexcomm3_lpi2c3, controller mode only */
#define I2C_BUS_LCD_HEADER 2 /* flexcomm2_lpi2c2 */

/* Canonical name for the shared sideband bus (IPMB 0x20 + MCTP 0x10). */
#define I2C_BUS_SIDEBAND I2C_BUS_LCD_HEADER

#endif
```
